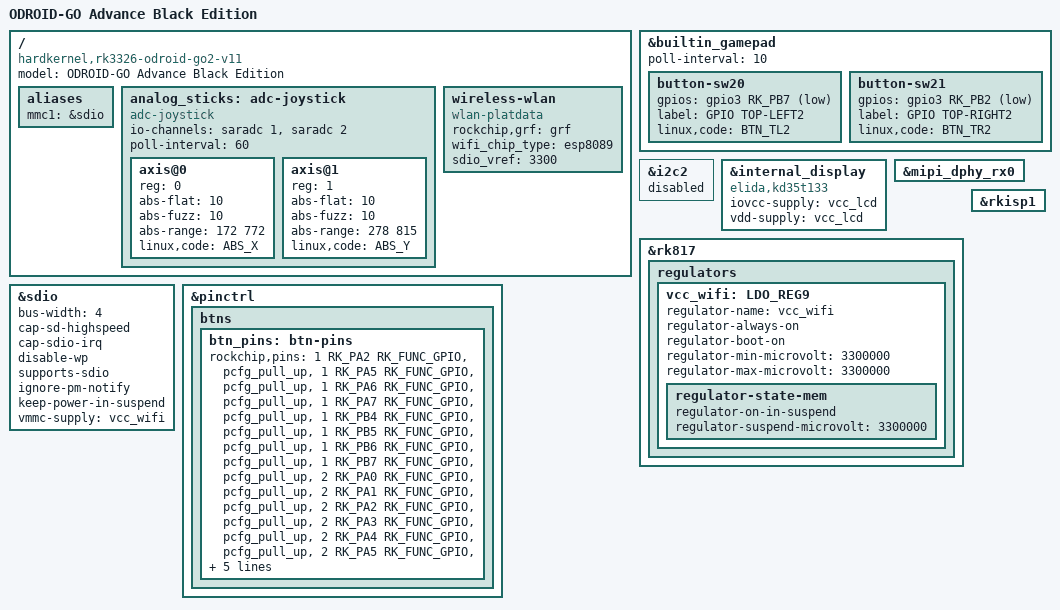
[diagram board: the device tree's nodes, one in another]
// SPDX-License-Identifier: (GPL-2.0+ OR MIT)
/*
 * Copyright (c) 2019 Hardkernel Co., Ltd
 * Copyright (c) 2020 Theobroma Systems Design und Consulting GmbH
 * Copyright (c) 2022 Maya Matuszczyk <maccraft123mc@gmail.com>
 */

/dts-v1/;
#include "rk3326-odroid-go.dtsi"

/ {
	model = "ODROID-GO Advance Black Edition";
	compatible = "hardkernel,rk3326-odroid-go2-v11", "rockchip,rk3326";

	aliases {
		mmc1 = &sdio;
	};

	analog_sticks: adc-joystick {
		compatible = "adc-joystick";
		io-channels = <&saradc 1>,
			      <&saradc 2>;
		poll-interval = <60>;
		#address-cells = <1>;
		#size-cells = <0>;

		axis@0 {
			reg = <0>;
			abs-flat = <10>;
			abs-fuzz = <10>;
			abs-range = <172 772>;
			linux,code = <ABS_X>;
			};

		axis@1 {
			reg = <1>;
			abs-flat = <10>;
			abs-fuzz = <10>;
			abs-range = <278 815>;
			linux,code = <ABS_Y>;
		};
	};

	wireless-wlan {
		compatible = "wlan-platdata";
		rockchip,grf = <&grf>;
		/* wifi_chip_type - wifi chip define
		* ap6210, ap6330, ap6335
		* rtl8188eu, rtl8723bs, rtl8723bu
		* esp8089
		*/
		wifi_chip_type = "esp8089";
		sdio_vref = <3300>; //1800mv or 3300mv
		status = "okay";
	};
};

&builtin_gamepad {
	/* poll device interval (ms), adc read interval */
	poll-interval = <10>;

	button-sw20 {
		gpios = <&gpio3 RK_PB7 GPIO_ACTIVE_LOW>;
		label = "GPIO TOP-LEFT2";
		linux,code = <BTN_TL2>;
	};
	button-sw21 {
		gpios = <&gpio3 RK_PB2 GPIO_ACTIVE_LOW>;
		label = "GPIO TOP-RIGHT2";
		linux,code = <BTN_TR2>;
	};
};

/* MIPI CSI I2C */
&i2c2 {
	status = "disabled";
};

&internal_display {
	compatible = "elida,kd35t133", "simple-panel-dsi";
	iovcc-supply = <&vcc_lcd>;
	vdd-supply = <&vcc_lcd>;
};

&mipi_dphy_rx0 {
	status = "okay";
};

&rk817 {
	regulators {
		/* Rev 1.1 WIFI Power */
		vcc_wifi: LDO_REG9 {
			regulator-name = "vcc_wifi";
			regulator-always-on;
			regulator-boot-on;
			regulator-min-microvolt = <3300000>;
			regulator-max-microvolt = <3300000>;

			regulator-state-mem {
				regulator-on-in-suspend;
				regulator-suspend-microvolt = <3300000>;
			};
		};
	};
};

&rkisp1 {
	status = "okay";
};

&sdio {
	bus-width = <4>;
	cap-sd-highspeed;
	cap-sdio-irq;
	disable-wp;
	supports-sdio;
	ignore-pm-notify;
	keep-power-in-suspend;
	/* non-removable; */
	vmmc-supply = <&vcc_wifi>;
	status = "okay";
};

&pinctrl {
	btns {
		btn_pins: btn-pins {
			rockchip,pins = <1 RK_PA2 RK_FUNC_GPIO &pcfg_pull_up>,
					<1 RK_PA5 RK_FUNC_GPIO &pcfg_pull_up>,
					<1 RK_PA6 RK_FUNC_GPIO &pcfg_pull_up>,
					<1 RK_PA7 RK_FUNC_GPIO &pcfg_pull_up>,
					<1 RK_PB4 RK_FUNC_GPIO &pcfg_pull_up>,
					<1 RK_PB5 RK_FUNC_GPIO &pcfg_pull_up>,
					<1 RK_PB6 RK_FUNC_GPIO &pcfg_pull_up>,
					<1 RK_PB7 RK_FUNC_GPIO &pcfg_pull_up>,
					<2 RK_PA0 RK_FUNC_GPIO &pcfg_pull_up>,
					<2 RK_PA1 RK_FUNC_GPIO &pcfg_pull_up>,
					<2 RK_PA2 RK_FUNC_GPIO &pcfg_pull_up>,
					<2 RK_PA3 RK_FUNC_GPIO &pcfg_pull_up>,
					<2 RK_PA4 RK_FUNC_GPIO &pcfg_pull_up>,
					<2 RK_PA5 RK_FUNC_GPIO &pcfg_pull_up>,
					<2 RK_PA6 RK_FUNC_GPIO &pcfg_pull_up>,
					<2 RK_PA7 RK_FUNC_GPIO &pcfg_pull_up>,
					<3 RK_PB2 RK_FUNC_GPIO &pcfg_pull_up>,
					<3 RK_PB7 RK_FUNC_GPIO &pcfg_pull_up>;
		};
	};
};
